AUTOSAR XML (schema 314)
package /ComponentType
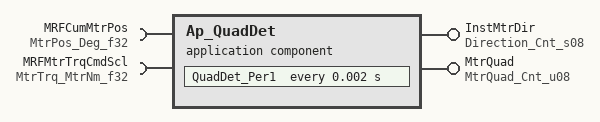
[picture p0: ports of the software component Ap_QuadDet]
  application software component type Ap_QuadDet
    provide port InstMtrDir: unqueued-sender-com-spec{data-element=Cnt_s08, can-invalidate=false, init-value=D_ZERO_CNT_S8}, provided-interface=Direction_Cnt_s08
    provide port MtrQuad: unqueued-sender-com-spec{data-element=Cnt_u08, can-invalidate=false, init-value=D_QUADRANT1_CNT_U8}, provided-interface=MtrQuad_Cnt_u08
    require port MRFCumMtrPos: unqueued-receiver-com-spec{data-element=Deg_f32, init-value=D_ZERO_ULS_F32}, required-interface=MtrPos_Deg_f32
    require port MRFMtrTrqCmdScl: unqueued-receiver-com-spec{data-element=MtrNm_f32, init-value=D_ZERO_ULS_F32}, required-interface=MtrTrq_MtrNm_f32
  internal behavior Ap_QuadDet_InternalBehavior: component=Ap_QuadDet
    timing event TMT_QuadDet_Per1: start-on-event=QuadDet_Per1, period=0.002
    port-api-options:
      enable-take-address=false, indirect-api=false, port=InstMtrDir
      enable-take-address=false, indirect-api=false, port=MRFCumMtrPos
      enable-take-address=false, indirect-api=false, port=MRFMtrTrqCmdScl
      enable-take-address=false, indirect-api=false, port=MtrQuad
    runnable QuadDet_Per1
      data read access READ_MRFCumMtrPos_Deg_f32: data-element=MRFCumMtrPos.Deg_f32
      data read access READ_MRFMtrTrqCmdScl_MtrNm_f32: data-element=MRFMtrTrqCmdScl.MtrNm_f32
      data write access WRITE_InstMtrDir_Cnt_s08: data-element=InstMtrDir.Cnt_s08
      data write access WRITE_MtrQuad_Cnt_u08: data-element=MtrQuad.Cnt_u08
  swc implementation Ap_QuadDet_Implementation: behavior=Ap_QuadDet_InternalBehavior
    code-descriptors:
      code Code: type=SRC
